# CY8C5868AXI_LP035 register map
File version: 0.1
CY8C58LP
Registers are 8-bit, read-write, no defined reset value unless marked. A register's access mark holds for its fields unless they carry their own. Offsets are from the block's base; lines under a group give offsets from that group; [hi:lo] are bit positions; {n}, {i} and the like mark numbered series; 'fields as' and 'values as' point back to an identical list; <NAME> marks a mode.

## Memory map
0x40004394 Launcher_UART size 0x1D0A — USBFS
0x400043A7 CapSense_CompCH0 size 0x17F0
0x400043A8 CapSense_IdacCH0 size 0x17D9
0x4000642F Target_UART size 0x41 — UART
0x4000647C CapSense size 0x20

## Launcher_UART — USBFS
Base 0x40004394
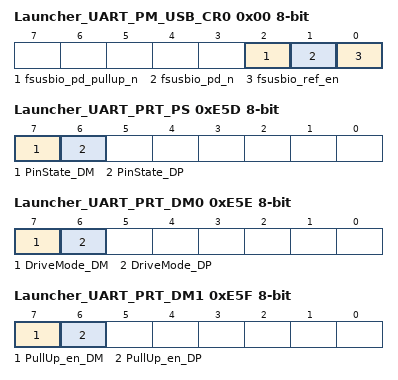
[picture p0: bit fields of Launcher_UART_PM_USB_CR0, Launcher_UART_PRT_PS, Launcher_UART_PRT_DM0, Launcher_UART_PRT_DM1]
0x00 Launcher_UART_PM_USB_CR0 — USB Power Mode Control Register 0
  [2] fsusbio_pd_pullup_n, [1] fsusbio_pd_n, [0] fsusbio_ref_en
0x11 Launcher_UART_PM_ACT_CFG — Active Power Mode Configuration Register
0x21 Launcher_UART_PM_STBY_CFG — Standby Power Mode Configuration Register
0xE5D Launcher_UART_PRT_PS — Port Pin State Register
  [7] PinState_DM ro, [6] PinState_DP ro
0xE5E Launcher_UART_PRT_DM0 — Port Drive Mode Register
  [7] DriveMode_DM, [6] DriveMode_DP
0xE5F Launcher_UART_PRT_DM1 — Port Drive Mode Register
  [7] PullUp_en_DM, [6] PullUp_en_DP
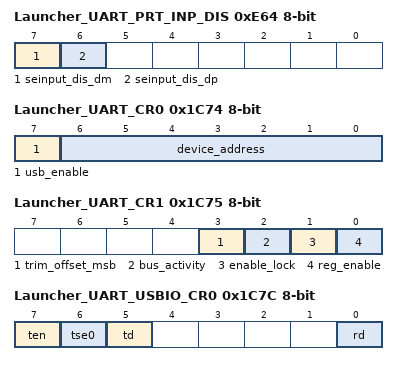
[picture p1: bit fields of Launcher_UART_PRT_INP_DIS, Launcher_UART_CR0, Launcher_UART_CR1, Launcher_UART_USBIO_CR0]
0xE64 Launcher_UART_PRT_INP_DIS — Input buffer disable override
  [7] seinput_dis_dm, [6] seinput_dis_dp
0x1C6C Launcher_UART_EP0_DR0 — bmRequestType
0x1C6D Launcher_UART_EP0_DR1 — bRequest
0x1C6E Launcher_UART_EP0_DR2 — wValueLo
0x1C6F Launcher_UART_EP0_DR3 — wValueHi
0x1C70 Launcher_UART_EP0_DR4 — wIndexLo
0x1C71 Launcher_UART_EP0_DR5 — wIndexHi
0x1C72 Launcher_UART_EP0_DR6 — lengthLo
0x1C73 Launcher_UART_EP0_DR7 — lengthHi
0x1C74 Launcher_UART_CR0 — USB Control Register 0
  [7] usb_enable, [6:0] device_address ro
0x1C75 Launcher_UART_CR1 — USB Control Register 1
  [3] trim_offset_msb, [2] bus_activity, [1] enable_lock, [0] reg_enable
{0x1C6A+0x10*i} Launcher_UART_SIE_EP{i}_CR0 (i=1..8) — The Endpoint{i} Control Register
0x1C7C Launcher_UART_USBIO_CR0 — USBIO Control Register 0
  [7] ten, [6] tse0, [5] td, [0] rd ro
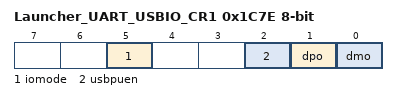
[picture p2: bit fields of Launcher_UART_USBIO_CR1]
0x1C7E Launcher_UART_USBIO_CR1 — USBIO Control Register 1
  [5] iomode, [2] usbpuen, [1] dpo ro, [0] dmo ro
0x1CF8 Launcher_UART_BUF_SIZE — Dedicated Endpoint Buffer Size Register
0x1CFA Launcher_UART_EP_ACTIVE — Endpoint Active Indication Register
0x1CFB Launcher_UART_EP_TYPE — Endpoint Type (IN/OUT) Indication
0x1D09 Launcher_UART_USB_CLK_EN — USB Block Clock Enable Register

## CapSense
Base 0x4000647C
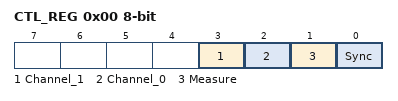
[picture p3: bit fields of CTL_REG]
0x00 CTL_REG — CapSense Control Register
  [3] Channel_1 ro — Channel 1 Enable
    0=Disabled (Channel 1 scanning is disabled); 1=Enabled (Channel 1 scanning is enabled)
  [2] Channel_0 ro — Channel 0 Enable
    0=Disabled (Channel 0 scanning is disabled); 1=Enabled (Channel 0 scanning is enabled)
  [1] Measure ro — Measurement Enable
    0=Disabled (Capacitance measurement is disabled); 1=Enabled (Capacitance measurement is enabled)
  [0] Sync ro — Reset Digital and Pre-Charge Clocks
    0=Disabled (Clocks are in the reset state); 1=Enabled (Clocks are enabled)
0x1F ScanSpeed_CTL_REG — CapSense Clock Prescaler Control Register
  [3] Counter ro — Clock Prescaler Enable
    0=Disabled (Prescaler counter is disabled); 1=Enabled (Prescaler counter is enabled)

## CapSense_IdacCH0
Base 0x400043A8
0x00 IDAC8_PM_ACT_CFG — Active Power Mode Configuration Register 8
  [3:0] en_dac — Enable DAC block(s). Populated subsystems are counted from the LSB.
0x10 IDAC8_PM_STBY_CFG — Standby Power Mode Configuration Register 8
  fields as IDAC8_PM_ACT_CFG
0x260 IDAC8_TR
  [7:0] tr — 8 Calibration bits
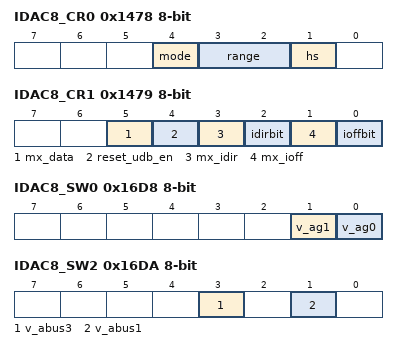
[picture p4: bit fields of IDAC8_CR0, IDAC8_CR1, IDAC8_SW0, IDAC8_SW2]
0x1478 IDAC8_CR0 — DAC Block Control Register 0
  [4] mode ro — Mode Bit
    0=DAC_MODE_V (voltage DAC); 1=DAC_MODE_I (current DAC)
  [3:2] range — Ranges for mode=0 (VDAC) and mode=1 (IDAC)
    0=DAC_RANGE_0 (x0=0V to 4*vref (1.024V); 0 to 31.875uA); 1=DAC_RANGE_1 (x1=0V to 16*vref (4.096V); 0 to 255uA); 2=DAC_RANGE_2 (x0=0V to 4*vref (1.024V); 0 to 2.040mA); 3=DAC_RANGE_3 (x1=0V to 16*vref (4.096V); not used)
  [1] hs — High Speed Bit
    0=DAC_HS_LOWPOWER (regular (low power)); 1=DAC_HS_HIGHSPEED (high speed (higher power))
0x1479 IDAC8_CR1 — DAC Block Control Register 1
  [5] mx_data — Select DATA source
    0=MX_DATA_REG (Select register source); 1=MX_DATA_UDB (Select UDB source)
  [4] reset_udb_en — DAC reset enable
    0=RESET_UDB_EN_DISABLE (Disable DAC Reset Source from UDB); 1=RESET_UDB_EN_ENABLE (Enable DAC Reset Source from UDB)
  [3] mx_idir — Mux selection for DAC current direction control
    0=MX_IDIR_REG (Register source idirbit selected); 1=MX_IDIR_UDB (UDB ictrl selected)
  [2] idirbit — register source for DAC current direction
  [1] mx_ioff — Mux selection for DAC current off control
    0=MX_IOFF_REG (Register source ioffbit selected); 1=MX_IOFF_UDB (UDB ictrl selected)
  [0] ioffbit — register source for DAC current off
0x16D8 IDAC8_SW0 — DAC Analog Routing Register 0
  [1] v_ag1 — Connect voltage output to analog global of same side
    0=AG_NC (not connected); 1=AG_CONNECTED (Connect to Analog Global)
  [0] v_ag0 — Connect voltage output to analog global of same side
    values as v_ag1
0x16DA IDAC8_SW2 — DAC Analog Routing Register 2
  [3] v_abus3 — Connect voltage output to analog (local) bus of the same side
    0=ABUS_NC (not connected); 1=ABUS_CONNECTED (Connect to Analog (local) Bus)
  [1] v_abus1 — Connect voltage output to analog (local) bus of the same side
    values as v_abus3
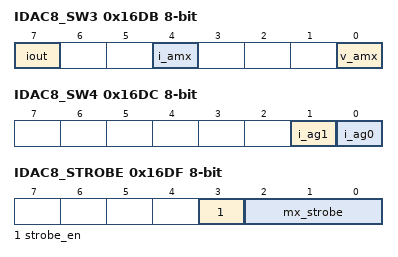
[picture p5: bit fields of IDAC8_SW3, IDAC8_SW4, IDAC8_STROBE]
0x16DB IDAC8_SW3 — DAC Analog Routing Register 3
  [7] iout — Connect current output to pad
    0=IOUT_NC (not connected); 1=IOUT_CONNECT (Connect to pad)
  [4] i_amx — Connect current output to Analog Mux Bus
    0=AMX_NC (not connected); 1=AMX_CONNECTED (Connect to AMUXBUS)
  [0] v_amx — Connect voltage output to Analog Mux Bus
    values as i_amx
0x16DC IDAC8_SW4 — DAC Analog Routing Register 4
  [1] i_ag1 — Connect current output to analog global of same side
    values as IDAC8_SW0.v_ag1
  [0] i_ag0 — Connect current output to analog global of same side
    values as IDAC8_SW0.v_ag1
0x16DF IDAC8_STROBE — DAC Strobe Register
  [3] strobe_en — Strobe gating control
    0=disable strobe; 1=enable strobe
  [2:0] mx_strobe — Strobe source selection
    0=MX_STROBE_BUSWRITE (Select bus write strobe source); 1=MX_STROBE_UDB_SRC (Select UDB strobe source); 2=MX_STROBE_NC_2 (NC); 3=MX_STROBE_NC_3 (NC); {v}=MX_STROBE_CLK_A{v-4}_DIG (Select clk_a{v-4}_dig) (v=4..7)
0x17D8 IDAC8_D — DAC Data Register
  [7:0] data — 8 DAC Data bits
